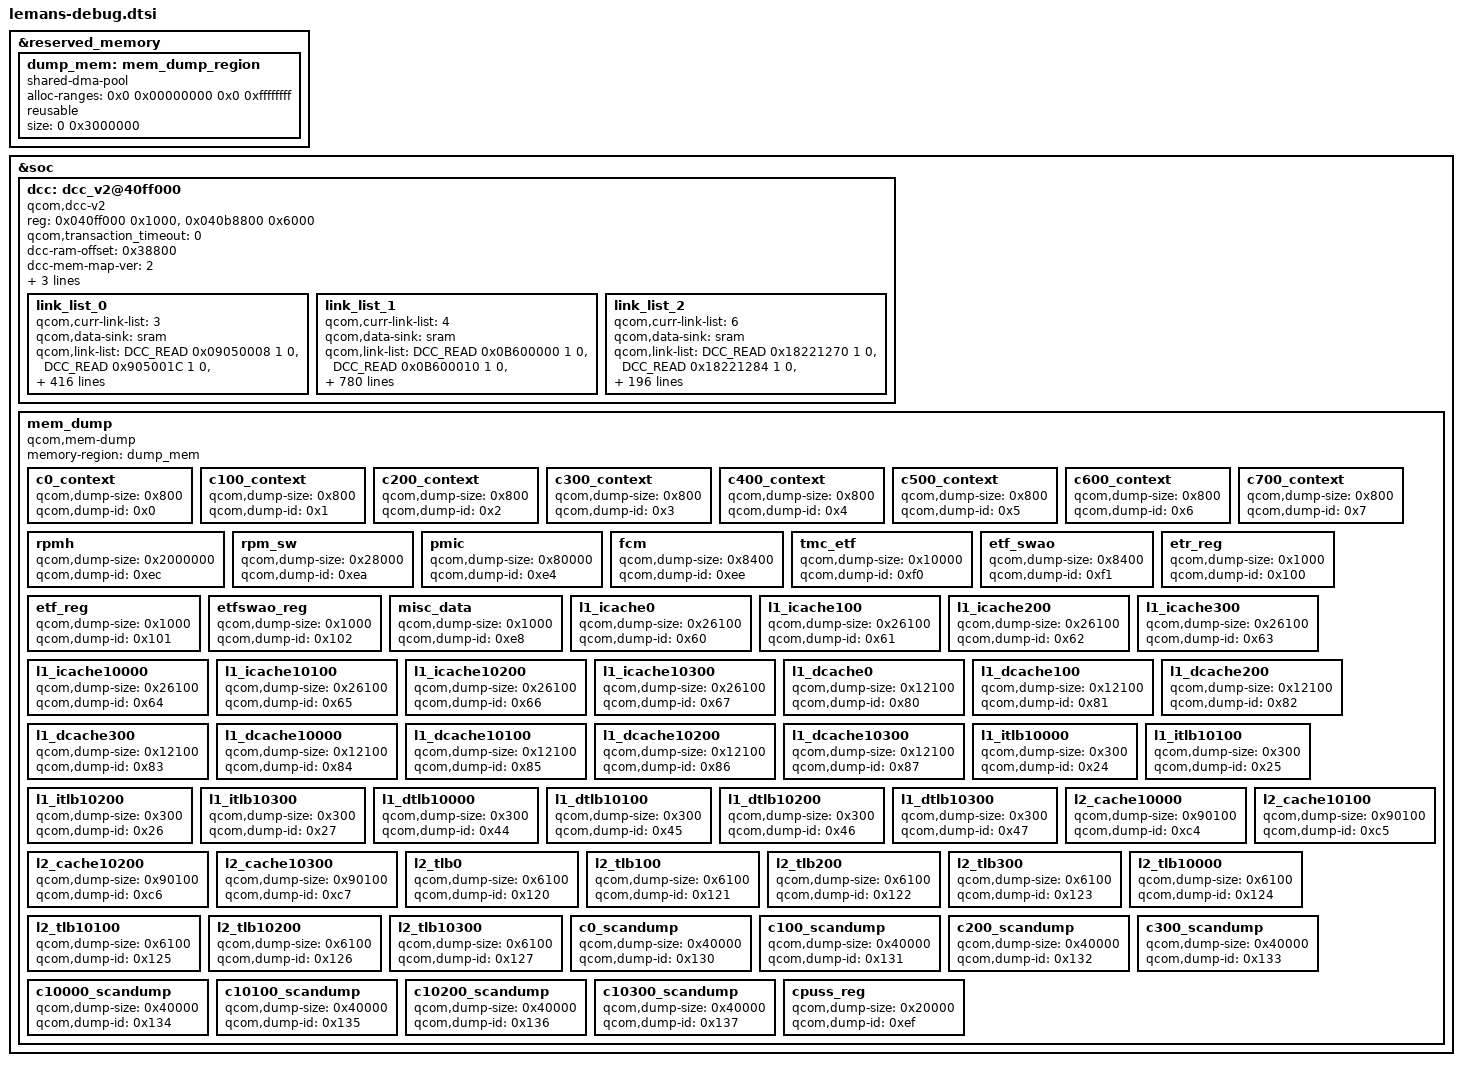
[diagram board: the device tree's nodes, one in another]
#include <dt-bindings/soc/qcom,dcc_v2.h>

&reserved_memory {
	#address-cells = <2>;
	#size-cells = <2>;
	ranges;

	dump_mem: mem_dump_region {
		compatible = "shared-dma-pool";
		alloc-ranges = <0x0 0x00000000 0x0 0xffffffff>;
		reusable;
		size = <0 0x3000000>;
	};
};

&soc {
	dcc: dcc_v2@40ff000 {
		compatible = "qcom,dcc-v2";
		reg = <0x040ff000 0x1000>,
			<0x040b8800 0x6000>;
		reg-names = "dcc-base", "dcc-ram-base";
		qcom,transaction_timeout = <0>;
		dcc-ram-offset = <0x38800>;
		dcc-mem-map-ver = <2>;
		per-ll-reg-cnt = <9>;
		ll-reg-offsets = <
			0x034 0x03C 0x040 0x044 0x04C 0x050 0x068 0x06C 0x038
			0x0B4 0x0BC 0x0C0 0x0C4 0x0CC 0x0D0 0x0E8 0x0EC 0x0B8
			0x134 0x13C 0x140 0x144 0x14C 0x150 0x168 0x16C 0x138
			0x1B4 0x1BC 0x1C0 0x1C4 0x1CC 0x1D0 0x1E8 0x1EC 0x1B8
			0x234 0x23C 0x240 0x244 0x24C 0x250 0x268 0x26C 0x238
			0x2B4 0x2BC 0x2C0 0x2C4 0x2CC 0x2D0 0x2E8 0x2EC 0x2B8
			0x334 0x33C 0x340 0x344 0x34C 0x350 0x368 0x36C 0x338
			0x3B4 0x3BC 0x3C0 0x3C4 0x3CC 0x3D0 0x3E8 0x3EC 0x3B8>;

		status = "okay";
		link_list_0 {
			qcom,curr-link-list = <3>;
			qcom,data-sink = "sram";
			qcom,link-list = <DCC_READ 0x09050008 1 0 >,
				<DCC_READ 0x905001C 1 0>,
				<DCC_READ 0x9050030 1 0>,
				<DCC_READ 0x9050050 1 0>,
				<DCC_READ 0x9050070 1 0>,
				<DCC_READ 0x9050948 1 0>,
				<DCC_READ 0x905104C 1 0>,
				<DCC_READ 0x09050078 1 0>,
				<DCC_READ 0x09050114 1 0>,
				<DCC_READ 0x90A0008 1 0>,
				<DCC_READ 0x90A000C 1 0>,
				<DCC_READ 0x90A0080 1 0>,
				<DCC_READ 0x90A1008 1 0>,
				<DCC_READ 0x90A100C 1 0>,
				<DCC_READ 0x90A1080 1 0>,
				<DCC_READ 0x90A80E4 1 0>,
				<DCC_READ 0x90A80E8 1 0>,
				<DCC_READ 0x90A816C 1 0>,
				<DCC_READ 0x90A8170 1 0>,
				<DCC_READ 0x90A80F8 1 0>,
				<DCC_READ 0x90A8180 1 0>,
				<DCC_READ 0x90A8184 1 0>,
				<DCC_READ 0x90A81A0 1 0>,
				<DCC_READ 0x90A81A4 1 0>,
				<DCC_READ 0x90A81C0 1 0>,
				<DCC_READ 0x90A81C4 1 0>,
				<DCC_READ 0x90A81E4 1 0>,
				<DCC_READ 0x90A81F4 1 0>,
				<DCC_READ 0x90A8204 1 0>,
				<DCC_READ 0x90A8218 1 0>,
				<DCC_READ 0x90A8228 1 0>,
				<DCC_READ 0x90A8264 1 0>,
				<DCC_READ 0x90A8268 1 0>,
				<DCC_READ 0x90A8270 1 0>,
				<DCC_READ 0x90A80FC 1 0>,
				<DCC_READ 0x90A8100 1 0>,
				<DCC_READ 0x90A8104 1 0>,
				<DCC_READ 0x90A8108 1 0>,
				<DCC_READ 0x90A8148 1 0>,
				<DCC_READ 0x90A814C 1 0>,
				<DCC_READ 0x90A8158 1 0>,
				<DCC_READ 0x90A815C 1 0>,
				<DCC_READ 0x90A8190 1 0>,
				<DCC_READ 0x90A8194 1 0>,
				<DCC_READ 0x90A81B0 1 0>,
				<DCC_READ 0x90A81B4 1 0>,
				<DCC_READ 0x90A81D0 1 0>,
				<DCC_READ 0x90A81D4 1 0>,
				<DCC_READ 0x90A84F4 1 0>,
				<DCC_READ 0x90A8138 1 0>,
				<DCC_READ 0x90A8150 1 0>,
				<DCC_READ 0x90A8160 1 0>,
				<DCC_READ 0x90A8198 1 0>,
				<DCC_READ 0x90A81B8 1 0>,
				<DCC_READ 0x90A81D8 1 0>,
				<DCC_READ 0x90A8280 1 0>,
				<DCC_READ 0x90A819C 1 0>,
				<DCC_READ 0x90A81BC 1 0>,
				<DCC_READ 0x90A81DC 1 0>,
				<DCC_READ 0x90A821C 1 0>,
				<DCC_READ 0x90A822C 1 0>,
				<DCC_READ 0x90A84F8 1 0>,
				<DCC_READ 0x90A9204 1 0>,
				<DCC_READ 0x90A880C 1 0>,
				<DCC_READ 0x90A8834 1 0>,
				<DCC_READ 0x90A8840 1 0>,
				<DCC_READ 0x90A8844 1 0>,
				<DCC_READ 0x90A8850 1 0>,
				<DCC_READ 0x90A8854 1 0>,
				<DCC_READ 0x90A8860 1 0>,
				<DCC_READ 0x90A8864 1 0>,
				<DCC_READ 0x90A8868 1 0>,
				<DCC_READ 0x90A8878 1 0>,
				<DCC_READ 0x90A9260 1 0>,
				<DCC_READ 0x90A8900 1 0>,
				<DCC_READ 0x90A9134 1 0>,
				<DCC_READ 0x90A9138 1 0>,
				<DCC_READ 0x90A8880 1 0>,
				<DCC_READ 0x90A8884 1 0>,
				<DCC_READ 0x90A8888 1 0>,
				<DCC_READ 0x90E0000 1 0>,
				<DCC_READ 0x90E0008 1 0>,
				<DCC_READ 0x90E0010 1 0>,
				<DCC_READ 0x90E0020 1 0>,
				<DCC_READ 0x90E0024 1 0>,
				<DCC_READ 0x90E0028 1 0>,
				<DCC_READ 0x90E002C 1 0>,
				<DCC_READ 0x90E0030 1 0>,
				<DCC_READ 0x90E0034 1 0>,
				<DCC_READ 0x90E0038 1 0>,
				<DCC_READ 0x90E003C 1 0>,
				<DCC_READ 0x90E0248 1 0>,
				<DCC_READ 0x90E3100 1 0>,
				<DCC_READ 0x90E4100 1 0>,
				<DCC_READ 0x90E4104 1 0>,
				<DCC_READ 0x90E4108 1 0>,
				<DCC_READ 0x90E410C 1 0>,
				<DCC_READ 0x90E4110 1 0>,
				<DCC_READ 0x90E4114 1 0>,
				<DCC_READ 0x90E4118 1 0>,
				<DCC_READ 0x90E5008 1 0>,
				<DCC_READ 0x90E5010 1 0>,
				<DCC_READ 0x90E5014 1 0>,
				<DCC_READ 0x90E5018 1 0>,
				<DCC_READ 0x9080024 1 0>,
				<DCC_READ 0x908002C 1 0>,
				<DCC_READ 0x9080034 1 0>,
				<DCC_READ 0x908003C 1 0>,
				<DCC_READ 0x9080044 1 0>,
				<DCC_READ 0x908004C 1 0>,
				<DCC_READ 0x9080054 1 0>,
				<DCC_READ 0x9080058 1 0>,
				<DCC_READ 0x908005C 1 0>,
				<DCC_READ 0x90800B8 1 0>,
				<DCC_READ 0x90800BC 1 0>,
				<DCC_READ 0x90800C8 1 0>,
				<DCC_READ 0x90800D4 1 0>,
				<DCC_READ 0x90800E0 1 0>,
				<DCC_READ 0x90800EC 1 0>,
				<DCC_READ 0x90800F8 1 0>,
				<DCC_READ 0x9080104 1 0>,
				<DCC_READ 0x9080108 1 0>,
				<DCC_READ 0x9080114 1 0>,
				<DCC_READ 0x9080144 1 0>,
				<DCC_READ 0x908014C 1 0>,
				<DCC_READ 0x9080168 1 0>,
				<DCC_READ 0x9080174 1 0>,
				<DCC_READ 0x90801AC 1 0>,
				<DCC_READ 0x90801B4 1 0>,
				<DCC_READ 0x90801BC 1 0>,
				<DCC_READ 0x90801C4 1 0>,
				<DCC_READ 0x90801CC 1 0>,
				<DCC_READ 0x90801D4 1 0>,
				<DCC_READ 0x90801DC 1 0>,
				<DCC_READ 0x90801E4 1 0>,
				<DCC_READ 0x90801EC 1 0>,
				<DCC_READ 0x90801F4 1 0>,
				<DCC_READ 0x90801F8 1 0>,
				<DCC_READ 0x90BA000 1 0>,
				<DCC_READ 0x90BA050 1 0>,
				<DCC_READ 0x090BA280 1 0>,
				<DCC_READ 0x090BA288 1 0>,
				<DCC_READ 0x9280610 1 0>,
				<DCC_READ 0x9280618 1 0>,
				<DCC_READ 0x928061C 1 0>,
				<DCC_READ 0x9280680 1 0>,
				<DCC_READ 0x9280684 1 0>,
				<DCC_READ 0x9280688 1 0>,
				<DCC_READ 0x928068C 1 0>,
				<DCC_READ 0x9380610 1 0>,
				<DCC_READ 0x9280614 1 0>,
				<DCC_READ 0x9380618 1 0>,
				<DCC_READ 0x938061C 1 0>,
				<DCC_READ 0x9380680 1 0>,
				<DCC_READ 0x9380684 1 0>,
				<DCC_READ 0x9380688 1 0>,
				<DCC_READ 0x938068C 1 0>,
				<DCC_READ 0x9480610 1 0>,
				<DCC_READ 0x9480614 1 0>,
				<DCC_READ 0x9480618 1 0>,
				<DCC_READ 0x948061C 1 0>,
				<DCC_READ 0x9480680 1 0>,
				<DCC_READ 0x9480684 1 0>,
				<DCC_READ 0x9480688 1 0>,
				<DCC_READ 0x948068C 1 0>,
				<DCC_READ 0x9580610 1 0>,
				<DCC_READ 0x9580614 1 0>,
				<DCC_READ 0x9580618 1 0>,
				<DCC_READ 0x958061C 1 0>,
				<DCC_READ 0x9580680 1 0>,
				<DCC_READ 0x9580684 1 0>,
				<DCC_READ 0x9580688 1 0>,
				<DCC_READ 0x958068C 1 0>,
				<DCC_READ 0x9680610 1 0>,
				<DCC_READ 0x9680614 1 0>,
				<DCC_READ 0x9680618 1 0>,
				<DCC_READ 0x968061C 1 0>,
				<DCC_READ 0x9680680 1 0>,
				<DCC_READ 0x9680684 1 0>,
				<DCC_READ 0x9680688 1 0>,
				<DCC_READ 0x968068C 1 0>,
				<DCC_READ 0x96B1300 4 0>,
				<DCC_READ 0x96B6138 3 0>,
				<DCC_READ 0x96B6D38 3 0>,
				<DCC_READ 0x96B7C04 3 0>,
				<DCC_READ 0x96B63D0 1 0>,
				<DCC_READ 0x96B63D8 1 0>,
				<DCC_READ 0x96B63E0 1 0>,
				<DCC_READ 0x96B6FD0 1 0>,
				<DCC_READ 0x96B6FD8 1 0>,
				<DCC_READ 0x96B6FE0 1 0>,
				<DCC_READ 0x96F1300 4 0>,
				<DCC_READ 0x96F6138 3 0>,
				<DCC_READ 0x96F6D38 3 0>,
				<DCC_READ 0x96F7C04 3 0>,
				<DCC_READ 0x96F63D0 1 0>,
				<DCC_READ 0x96F63D8 1 0>,
				<DCC_READ 0x96F63E0 1 0>,
				<DCC_READ 0x96F6FD0 1 0>,
				<DCC_READ 0x96F6FD8 1 0>,
				<DCC_READ 0x96F6FE0 1 0>,
				<DCC_READ 0x9731300 4 0>,
				<DCC_READ 0x9736138 3 0>,
				<DCC_READ 0x9736D38 3 0>,
				<DCC_READ 0x9737C04 3 0>,
				<DCC_READ 0x97363D0 1 0>,
				<DCC_READ 0x97363D8 1 0>,
				<DCC_READ 0x97363E0 1 0>,
				<DCC_READ 0x9736FD0 1 0>,
				<DCC_READ 0x9736FD8 1 0>,
				<DCC_READ 0x9736FE0 1 0>,
				<DCC_READ 0x9771300 4 0>,
				<DCC_READ 0x9776138 3 0>,
				<DCC_READ 0x9776D38 3 0>,
				<DCC_READ 0x9777C04 3 0>,
				<DCC_READ 0x97763D0 1 0>,
				<DCC_READ 0x97763D8 1 0>,
				<DCC_READ 0x97763E0 1 0>,
				<DCC_READ 0x9776FD0 1 0>,
				<DCC_READ 0x9776FD8 1 0>,
				<DCC_READ 0x9776FE0 1 0>,
				<DCC_READ 0x97B1300 4 0>,
				<DCC_READ 0x97B6138 3 0>,
				<DCC_READ 0x97B6D38 3 0>,
				<DCC_READ 0x97B7C04 3 0>,
				<DCC_READ 0x97B63D0 1 0>,
				<DCC_READ 0x97B63D8 1 0>,
				<DCC_READ 0x97B63E0 1 0>,
				<DCC_READ 0x97B6FD0 1 0>,
				<DCC_READ 0x97B6FD8 1 0>,
				<DCC_READ 0x97B6FE0 1 0>,
				<DCC_READ 0x97F1300 4 0>,
				<DCC_READ 0x97F6138 3 0>,
				<DCC_READ 0x97F6D38 3 0>,
				<DCC_READ 0x97F7C04 3 0>,
				<DCC_READ 0x97F63D0 1 0>,
				<DCC_READ 0x97F63D8 1 0>,
				<DCC_READ 0x97F63E0 1 0>,
				<DCC_READ 0x97F6FD0 1 0>,
				<DCC_READ 0x97F6FD8 1 0>,
				<DCC_READ 0x97F6FE0 1 0>,
				<DCC_READ 0x9831300 4 0>,
				<DCC_READ 0x9836138 3 0>,
				<DCC_READ 0x9836D38 3 0>,
				<DCC_READ 0x9837C04 3 0>,
				<DCC_READ 0x98363D0 1 0>,
				<DCC_READ 0x98363D8 1 0>,
				<DCC_READ 0x98363E0 1 0>,
				<DCC_READ 0x9836FD0 1 0>,
				<DCC_READ 0x9836FD8 1 0>,
				<DCC_READ 0x9836FE0 1 0>,
				<DCC_READ 0x9871300 4 0>,
				<DCC_READ 0x9876138 3 0>,
				<DCC_READ 0x9876D38 3 0>,
				<DCC_READ 0x9877C04 3 0>,
				<DCC_READ 0x98763D0 1 0>,
				<DCC_READ 0x98763D8 1 0>,
				<DCC_READ 0x98763E0 1 0>,
				<DCC_READ 0x9876FD0 1 0>,
				<DCC_READ 0x9876FD8 1 0>,
				<DCC_READ 0x9876FE0 1 0>,
				<DCC_READ 0x96B8D4C 1 0>,
				<DCC_READ 0x96B8D2C 1 0>,
				<DCC_READ 0x96B8D0C 1 0>,
				<DCC_READ 0x96F8D4C 1 0>,
				<DCC_READ 0x96F8D2C 1 0>,
				<DCC_READ 0x96F8D0C 1 0>,
				<DCC_READ 0x9738D4C 1 0>,
				<DCC_READ 0x9738D2C 1 0>,
				<DCC_READ 0x9738D0C 1 0>,
				<DCC_READ 0x9778D4C 1 0>,
				<DCC_READ 0x9778D2C 1 0>,
				<DCC_READ 0x9778D0C 1 0>,
				<DCC_READ 0x97B8D4C 1 0>,
				<DCC_READ 0x97B8D2C 1 0>,
				<DCC_READ 0x97B8D0C 1 0>,
				<DCC_READ 0x97F8D4C 1 0>,
				<DCC_READ 0x97F8D2C 1 0>,
				<DCC_READ 0x97F8D0C 1 0>,
				<DCC_READ 0x9838D4C 1 0>,
				<DCC_READ 0x9838D2C 1 0>,
				<DCC_READ 0x9838D0C 1 0>,
				<DCC_READ 0x9878D4C 1 0>,
				<DCC_READ 0x9878D2C 1 0>,
				<DCC_READ 0x9878D0C 1 0>,
				<DCC_READ 0x96B8D40 1 0>,
				<DCC_READ 0x96B8D50 1 0>,
				<DCC_READ 0x96B8D58 1 0>,
				<DCC_READ 0x96F8D40 1 0>,
				<DCC_READ 0x96F8D50 1 0>,
				<DCC_READ 0x96F8D58 1 0>,
				<DCC_READ 0x9738D40 1 0>,
				<DCC_READ 0x9738D50 1 0>,
				<DCC_READ 0x9738D58 1 0>,
				<DCC_READ 0x9778D40 1 0>,
				<DCC_READ 0x9778D50 1 0>,
				<DCC_READ 0x9778D58 1 0>,
				<DCC_READ 0x97B8D40 1 0>,
				<DCC_READ 0x97B8D50 1 0>,
				<DCC_READ 0x97B8D58 1 0>,
				<DCC_READ 0x97F8D40 1 0>,
				<DCC_READ 0x97F8D50 1 0>,
				<DCC_READ 0x97F8D58 1 0>,
				<DCC_READ 0x9838D40 1 0>,
				<DCC_READ 0x9838D50 1 0>,
				<DCC_READ 0x9838D58 1 0>,
				<DCC_READ 0x9878D40 1 0>,
				<DCC_READ 0x9878D50 1 0>,
				<DCC_READ 0x9878D58 1 0>,
				<DCC_READ 0x96B8D20 1 0>,
				<DCC_READ 0x96F8D20 1 0>,
				<DCC_READ 0x9738D20 1 0>,
				<DCC_READ 0x9778D20 1 0>,
				<DCC_READ 0x97B8D20 1 0>,
				<DCC_READ 0x97F8D20 1 0>,
				<DCC_READ 0x9838D20 1 0>,
				<DCC_READ 0x9878D20 1 0>,
				<DCC_READ 0x96B8904 1 0>,
				<DCC_READ 0x96B8308 2 0>,
				<DCC_READ 0x96B8108 1 0>,
				<DCC_READ 0x96B8508 1 0>,
				<DCC_READ 0x96F8904 1 0>,
				<DCC_READ 0x96F8308 2 0>,
				<DCC_READ 0x96F8108 1 0>,
				<DCC_READ 0x96F8508 1 0>,
				<DCC_READ 0x9738904 1 0>,
				<DCC_READ 0x9738308 2 0>,
				<DCC_READ 0x9738108 1 0>,
				<DCC_READ 0x9738508 1 0>,
				<DCC_READ 0x9778904 1 0>,
				<DCC_READ 0x9778308 2 0>,
				<DCC_READ 0x9778108 1 0>,
				<DCC_READ 0x9778508 1 0>,
				<DCC_READ 0x97B8904 1 0>,
				<DCC_READ 0x97B8308 2 0>,
				<DCC_READ 0x97B8108 1 0>,
				<DCC_READ 0x97B8508 1 0>,
				<DCC_READ 0x97F8904 1 0>,
				<DCC_READ 0x97F8308 2 0>,
				<DCC_READ 0x97F8108 1 0>,
				<DCC_READ 0x97F8508 1 0>,
				<DCC_READ 0x9838904 1 0>,
				<DCC_READ 0x9838308 2 0>,
				<DCC_READ 0x9838108 1 0>,
				<DCC_READ 0x9838508 1 0>,
				<DCC_READ 0x9878904 1 0>,
				<DCC_READ 0x9878308 2 0>,
				<DCC_READ 0x9878108 1 0>,
				<DCC_READ 0x9878508 1 0>,
				<DCC_WRITE 0x06E0A00C 0x00600007 1>,
				<DCC_WRITE 0x06E0A01C 0x00136800 1>,
				<DCC_READ 0x06E0A014 1 1>,
				<DCC_WRITE 0x06E0A01C 0x00136810 1>,
				<DCC_READ 0x06E0A014 1 1>,
				<DCC_WRITE 0x06E0A01C 0x00136820 1>,
				<DCC_READ 0x06E0A014 1 1>,
				<DCC_WRITE 0x06E0A01C 0x00136830 1>,
				<DCC_READ 0x06E0A014 1 1>,
				<DCC_WRITE 0x06E0A01C 0x00136840 1>,
				<DCC_READ 0x06E0A014 1 1>,
				<DCC_WRITE 0x06E0A01C 0x00136850 1>,
				<DCC_READ 0x06E0A014 1 1>,
				<DCC_WRITE 0x06E0A01C 0x00136860 1>,
				<DCC_READ 0x06E0A014 1 1>,
				<DCC_WRITE 0x06E0A01C 0x00136870 1>,
				<DCC_READ 0x06E0A014 1 1>,
				<DCC_WRITE 0x06E0A01C 0x0003e9a0 1>,
				<DCC_WRITE 0x06E0A01C 0x001368a0 1>,
				<DCC_READ 0x06E0A014 1 1>,
				<DCC_WRITE 0x06E0A01C 0x0003c0a0 1>,
				<DCC_WRITE 0x06E0A01C 0x001368a0 1>,
				<DCC_READ 0x06E0A014 1 1>,
				<DCC_WRITE 0x06E0A01C 0x0003d1a0 1>,
				<DCC_WRITE 0x06E0A01C 0x001368a0 1>,
				<DCC_READ 0x06E0A014 1 1>,
				<DCC_WRITE 0x06E0A01C 0x0003d2a0 1>,
				<DCC_WRITE 0x06E0A01C 0x001368a0 1>,
				<DCC_READ 0x06E0A014 1 1>,
				<DCC_WRITE 0x06E0A01C 0x0003d5a0 1>,
				<DCC_WRITE 0x06E0A01C 0x001368a0 1>,
				<DCC_READ 0x06E0A014 1 1>,
				<DCC_WRITE 0x06E0A01C 0x0003d6a0 1>,
				<DCC_WRITE 0x06E0A01C 0x001368a0 1>,
				<DCC_READ 0x06E0A014 1 1>,
				<DCC_WRITE 0x06E0A01C 0x0003e8a0 1>,
				<DCC_WRITE 0x06E0A01C 0x001368a0 1>,
				<DCC_READ 0x06E0A014 1 1>,
				<DCC_WRITE 0x06E0A01C 0x0003eea0 1>,
				<DCC_WRITE 0x06E0A01C 0x001368a0 1>,
				<DCC_READ 0x06E0A014 1 1>,
				<DCC_WRITE 0x06E0A01C 0x0003b1a0 1>,
				<DCC_WRITE 0x06E0A01C 0x001368a0 1>,
				<DCC_READ 0x06E0A014 1 1>,
				<DCC_WRITE 0x06E0A01C 0x0003b2a0 1>,
				<DCC_WRITE 0x06E0A01C 0x001368a0 1>,
				<DCC_READ 0x06E0A014 1 1>,
				<DCC_WRITE 0x06E0A01C 0x0003b5a0 1>,
				<DCC_WRITE 0x06E0A01C 0x001368a0 1>,
				<DCC_READ 0x06E0A014 1 1>,
				<DCC_WRITE 0x06E0A01C 0x0003b6a0 1>,
				<DCC_WRITE 0x06E0A01C 0x001368a0 1>,
				<DCC_READ 0x06E0A014 1 1>,
				<DCC_WRITE 0x06E0A01C 0x0003c2a0 1>,
				<DCC_WRITE 0x06E0A01C 0x001368a0 1>,
				<DCC_READ 0x06E0A014 1 1>,
				<DCC_WRITE 0x06E0A01C 0x0003c5a0 1>,
				<DCC_WRITE 0x06E0A01C 0x001368a0 1>,
				<DCC_READ 0x06E0A014 1 1>,
				<DCC_WRITE 0x06E0A01C 0x0003c6a0 1>,
				<DCC_WRITE 0x06E0A01C 0x001368a0 1>,
				<DCC_READ 0x06E0A014 1 1>,
				<DCC_WRITE 0x06E0A014 0x00020B38 1>,
				<DCC_WRITE 0x06E0A01C 0x000368B0 1>,
				<DCC_WRITE 0x06E0A01C 0x00000BA8 1>,
				<DCC_WRITE 0x06E0A01C 0x0013B6A0 1>,
				<DCC_WRITE 0x06E0A01C 0x00F1E000 1>,
				<DCC_WRITE 0x06E0A008 0x00000007 1>,
				<DCC_READ 0x09067E00 124 0>;
		};

		link_list_1 {
			qcom,curr-link-list = <4>;
			qcom,data-sink = "sram";
			qcom,link-list = <DCC_READ 0x0B600000 1 0>,
				<DCC_READ 0x0B600010 1 0>,
				<DCC_READ 0x0B600020 1 0>,
				<DCC_READ 0x0B600030 1 0>,
				<DCC_READ 0x0B600040 1 0>,
				<DCC_READ 0x0B600050 1 0>,
				<DCC_READ 0x0B600060 1 0>,
				<DCC_READ 0x0B600070 1 0>,
				<DCC_READ 0x0B600080 1 0>,
				<DCC_READ 0x0B600090 1 0>,
				<DCC_READ 0x0B6000A0 1 0>,
				<DCC_READ 0x0B6000B0 1 0>,
				<DCC_READ 0x0B6000C0 1 0>,
				<DCC_READ 0x0B6000D0 1 0>,
				<DCC_READ 0x0B610000 1 0>,
				<DCC_READ 0x0B610010 1 0>,
				<DCC_READ 0x0B610020 1 0>,
				<DCC_READ 0x0B610030 1 0>,
				<DCC_READ 0x0B610040 1 0>,
				<DCC_READ 0x0B610050 1 0>,
				<DCC_READ 0x0B610060 1 0>,
				<DCC_READ 0x0B610070 1 0>,
				<DCC_READ 0x0B610080 1 0>,
				<DCC_READ 0x0B610090 1 0>,
				<DCC_READ 0x0B6100A0 1 0>,
				<DCC_READ 0x0B6100B0 1 0>,
				<DCC_READ 0x0B6100C0 1 0>,
				<DCC_READ 0x0B6100D0 1 0>,
				<DCC_READ 0x0B620000 1 0>,
				<DCC_READ 0x0B620010 1 0>,
				<DCC_READ 0x0B620020 1 0>,
				<DCC_READ 0x0B620030 1 0>,
				<DCC_READ 0x0B620040 1 0>,
				<DCC_READ 0x0B620050 1 0>,
				<DCC_READ 0x0B620060 1 0>,
				<DCC_READ 0x0B620070 1 0>,
				<DCC_READ 0x0B620080 1 0>,
				<DCC_READ 0x0B620090 1 0>,
				<DCC_READ 0x0B6200A0 1 0>,
				<DCC_READ 0x0B6200B0 1 0>,
				<DCC_READ 0x0B6200C0 1 0>,
				<DCC_READ 0x0B6200D0 1 0>,
				<DCC_READ 0x0B630000 1 0>,
				<DCC_READ 0x0B630010 1 0>,
				<DCC_READ 0x0B630020 1 0>,
				<DCC_READ 0x0B630030 1 0>,
				<DCC_READ 0x0B630040 1 0>,
				<DCC_READ 0x0B630050 1 0>,
				<DCC_READ 0x0B630060 1 0>,
				<DCC_READ 0x0B630070 1 0>,
				<DCC_READ 0x0B630080 1 0>,
				<DCC_READ 0x0B630090 1 0>,
				<DCC_READ 0x0B6300A0 1 0>,
				<DCC_READ 0x0B6300B0 1 0>,
				<DCC_READ 0x0B6300C0 1 0>,
				<DCC_READ 0x0B6300D0 1 0>,
				<DCC_READ 0x0B640000 1 0>,
				<DCC_READ 0x0B640010 1 0>,
				<DCC_READ 0x0B640020 1 0>,
				<DCC_READ 0x0B640030 1 0>,
				<DCC_READ 0x0B640040 1 0>,
				<DCC_READ 0x0B640050 1 0>,
				<DCC_READ 0x0B640060 1 0>,
				<DCC_READ 0x0B640070 1 0>,
				<DCC_READ 0x0B640080 1 0>,
				<DCC_READ 0x0B640090 1 0>,
				<DCC_READ 0x0B6400A0 1 0>,
				<DCC_READ 0x0B6400B0 1 0>,
				<DCC_READ 0x0B6400C0 1 0>,
				<DCC_READ 0x0B6400D0 1 0>,
				<DCC_READ 0x0B650000 1 0>,
				<DCC_READ 0x0B650010 1 0>,
				<DCC_READ 0x0B650020 1 0>,
				<DCC_READ 0x0B650030 1 0>,
				<DCC_READ 0x0B650040 1 0>,
				<DCC_READ 0x0B650050 1 0>,
				<DCC_READ 0x0B650060 1 0>,
				<DCC_READ 0x0B650070 1 0>,
				<DCC_READ 0x0B650080 1 0>,
				<DCC_READ 0x0B650090 1 0>,
				<DCC_READ 0x0B6500A0 1 0>,
				<DCC_READ 0x0B6500B0 1 0>,
				<DCC_READ 0x0B6500C0 1 0>,
				<DCC_READ 0x0B6500D0 1 0>,
				<DCC_READ 0x0B660000 1 0>,
				<DCC_READ 0x0B660010 1 0>,
				<DCC_READ 0x0B660020 1 0>,
				<DCC_READ 0x0B660030 1 0>,
				<DCC_READ 0x0B660040 1 0>,
				<DCC_READ 0x0B660050 1 0>,
				<DCC_READ 0x0B660060 1 0>,
				<DCC_READ 0x0B660070 1 0>,
				<DCC_READ 0x0B660080 1 0>,
				<DCC_READ 0x0B660090 1 0>,
				<DCC_READ 0x0B6600A0 1 0>,
				<DCC_READ 0x0B6600B0 1 0>,
				<DCC_READ 0x0B6600C0 1 0>,
				<DCC_READ 0x0B6600D0 1 0>,
				<DCC_READ 0x0B670000 1 0>,
				<DCC_READ 0x0B670010 1 0>,
				<DCC_READ 0x0B670020 1 0>,
				<DCC_READ 0x0B670030 1 0>,
				<DCC_READ 0x0B670040 1 0>,
				<DCC_READ 0x0B670050 1 0>,
				<DCC_READ 0x0B670060 1 0>,
				<DCC_READ 0x0B670070 1 0>,
				<DCC_READ 0x0B670080 1 0>,
				<DCC_READ 0x0B670090 1 0>,
				<DCC_READ 0x0B6700A0 1 0>,
				<DCC_READ 0x0B6700B0 1 0>,
				<DCC_READ 0x0B6700C0 1 0>,
				<DCC_READ 0x0B6700D0 1 0>,
				<DCC_READ 0x0B680000 1 0>,
				<DCC_READ 0x0B680010 1 0>,
				<DCC_READ 0x0B680020 1 0>,
				<DCC_READ 0x0B680030 1 0>,
				<DCC_READ 0x0B680040 1 0>,
				<DCC_READ 0x0B680050 1 0>,
				<DCC_READ 0x0B680060 1 0>,
				<DCC_READ 0x0B680070 1 0>,
				<DCC_READ 0x0B680080 1 0>,
				<DCC_READ 0x0B680090 1 0>,
				<DCC_READ 0x0B6800A0 1 0>,
				<DCC_READ 0x0B6800B0 1 0>,
				<DCC_READ 0x0B6800C0 1 0>,
				<DCC_READ 0x0B6800D0 1 0>,
				<DCC_READ 0x0B690000 1 0>,
				<DCC_READ 0x0B690010 1 0>,
				<DCC_READ 0x0B690020 1 0>,
				<DCC_READ 0x0B690030 1 0>,
				<DCC_READ 0x0B690040 1 0>,
				<DCC_READ 0x0B690050 1 0>,
				<DCC_READ 0x0B690060 1 0>,
				<DCC_READ 0x0B690070 1 0>,
				<DCC_READ 0x0B690080 1 0>,
				<DCC_READ 0x0B690090 1 0>,
				<DCC_READ 0x0B6900A0 1 0>,
				<DCC_READ 0x0B6900B0 1 0>,
				<DCC_READ 0x0B6900C0 1 0>,
				<DCC_READ 0x0B6900D0 1 0>,
				<DCC_READ 0x0B6A0000 1 0>,
				<DCC_READ 0x0B6A0010 1 0>,
				<DCC_READ 0x0B6A0020 1 0>,
				<DCC_READ 0x0B6A0030 1 0>,
				<DCC_READ 0x0B6A0040 1 0>,
				<DCC_READ 0x0B6A0050 1 0>,
				<DCC_READ 0x0B6A0060 1 0>,
				<DCC_READ 0x0B6A0070 1 0>,
				<DCC_READ 0x0B6A0080 1 0>,
				<DCC_READ 0x0B6A0090 1 0>,
				<DCC_READ 0x0B6A00A0 1 0>,
				<DCC_READ 0x0B6A00B0 1 0>,
				<DCC_READ 0x0B6A00C0 1 0>,
				<DCC_READ 0x0B6A00D0 1 0>,
				<DCC_READ 0x0B6B0000 1 0>,
				<DCC_READ 0x0B6B0010 1 0>,
				<DCC_READ 0x0B6B0020 1 0>,
				<DCC_READ 0x0B6B0030 1 0>,
				<DCC_READ 0x0B6B0040 1 0>,
				<DCC_READ 0x0B6B0050 1 0>,
				<DCC_READ 0x0B6B0060 1 0>,
				<DCC_READ 0x0B6B0070 1 0>,
				<DCC_READ 0x0B6B0080 1 0>,
				<DCC_READ 0x0B6B0090 1 0>,
				<DCC_READ 0x0B6B00A0 1 0>,
				<DCC_READ 0x0B6B00B0 1 0>,
				<DCC_READ 0x0B6B00C0 1 0>,
				<DCC_READ 0x0B6B00D0 1 0>,
				<DCC_READ 0x0B6C0000 1 0>,
				<DCC_READ 0x0B6C0010 1 0>,
				<DCC_READ 0x0B6C0020 1 0>,
				<DCC_READ 0x0B6C0030 1 0>,
				<DCC_READ 0x0B6C0040 1 0>,
				<DCC_READ 0x0B6C0050 1 0>,
				<DCC_READ 0x0B6C0060 1 0>,
				<DCC_READ 0x0B6C0070 1 0>,
				<DCC_READ 0x0B6C0080 1 0>,
				<DCC_READ 0x0B6C0090 1 0>,
				<DCC_READ 0x0B6C00A0 1 0>,
				<DCC_READ 0x0B6C00B0 1 0>,
				<DCC_READ 0x0B6C00C0 1 0>,
				<DCC_READ 0x0B6C00D0 1 0>,
				<DCC_READ 0x0B6D0000 1 0>,
				<DCC_READ 0x0B6D0010 1 0>,
				<DCC_READ 0x0B6D0020 1 0>,
				<DCC_READ 0x0B6D0030 1 0>,
				<DCC_READ 0x0B6D0040 1 0>,
				<DCC_READ 0x0B6D0050 1 0>,
				<DCC_READ 0x0B6D0060 1 0>,
				<DCC_READ 0x0B6D0070 1 0>,
				<DCC_READ 0x0B6D0080 1 0>,
				<DCC_READ 0x0B6D0090 1 0>,
				<DCC_READ 0x0B6D00A0 1 0>,
				<DCC_READ 0x0B6D00B0 1 0>,
				<DCC_READ 0x0B6D00C0 1 0>,
				<DCC_READ 0x0B6D00D0 1 0>,
				<DCC_READ 0x0B6E0000 1 0>,
				<DCC_READ 0x0B6E0010 1 0>,
				<DCC_READ 0x0B6E0020 1 0>,
				<DCC_READ 0x0B6E0030 1 0>,
				<DCC_READ 0x0B6E0040 1 0>,
				<DCC_READ 0x0B6E0050 1 0>,
				<DCC_READ 0x0B6E0060 1 0>,
				<DCC_READ 0x0B6E0070 1 0>,
				<DCC_READ 0x0B6E0080 1 0>,
				<DCC_READ 0x0B6E0090 1 0>,
				<DCC_READ 0x0B6E00A0 1 0>,
				<DCC_READ 0x0B6E00B0 1 0>,
				<DCC_READ 0x0B6E00C0 1 0>,
				<DCC_READ 0x0B6E00D0 1 0>,
				<DCC_READ 0x0B6F0000 1 0>,
				<DCC_READ 0x0B6F0010 1 0>,
				<DCC_READ 0x0B6F0020 1 0>,
				<DCC_READ 0x0B6F0030 1 0>,
				<DCC_READ 0x0B6F0040 1 0>,
				<DCC_READ 0x0B6F0050 1 0>,
				<DCC_READ 0x0B6F0060 1 0>,
				<DCC_READ 0x0B6F0070 1 0>,
				<DCC_READ 0x0B6F0080 1 0>,
				<DCC_READ 0x0B6F0090 1 0>,
				<DCC_READ 0x0B6F00A0 1 0>,
				<DCC_READ 0x0B6F00B0 1 0>,
				<DCC_READ 0x0B6F00C0 1 0>,
				<DCC_READ 0x0B6F00D0 1 0>,
				<DCC_READ 0x0B700000 1 0>,
				<DCC_READ 0x0B700010 1 0>,
				<DCC_READ 0x0B700020 1 0>,
				<DCC_READ 0x0B700030 1 0>,
				<DCC_READ 0x0B700040 1 0>,
				<DCC_READ 0x0B700050 1 0>,
				<DCC_READ 0x0B700060 1 0>,
				<DCC_READ 0x0B700070 1 0>,
				<DCC_READ 0x0B700080 1 0>,
				<DCC_READ 0x0B700090 1 0>,
				<DCC_READ 0x0B7000A0 1 0>,
				<DCC_READ 0x0B7000B0 1 0>,
				<DCC_READ 0x0B7000C0 1 0>,
				<DCC_READ 0x0B7000D0 1 0>,
				<DCC_READ 0x0B710000 1 0>,
				<DCC_READ 0x0B710010 1 0>,
				<DCC_READ 0x0B710020 1 0>,
				<DCC_READ 0x0B710030 1 0>,
				<DCC_READ 0x0B710040 1 0>,
				<DCC_READ 0x0B710050 1 0>,
				<DCC_READ 0x0B710060 1 0>,
				<DCC_READ 0x0B710070 1 0>,
				<DCC_READ 0x0B710080 1 0>,
				<DCC_READ 0x0B710090 1 0>,
				<DCC_READ 0x0B7100A0 1 0>,
				<DCC_READ 0x0B7100B0 1 0>,
				<DCC_READ 0x0B7100C0 1 0>,
				<DCC_READ 0x0B7100D0 1 0>,
				<DCC_READ 0x0B720000 1 0>,
				<DCC_READ 0x0B720010 1 0>,
				<DCC_READ 0x0B720020 1 0>,
				<DCC_READ 0x0B720030 1 0>,
				<DCC_READ 0x0B720040 1 0>,
				<DCC_READ 0x0B720050 1 0>,
				<DCC_READ 0x0B720060 1 0>,
				<DCC_READ 0x0B720070 1 0>,
				<DCC_READ 0x0B720080 1 0>,
				<DCC_READ 0x0B720090 1 0>,
				<DCC_READ 0x0B7200A0 1 0>,
				<DCC_READ 0x0B7200B0 1 0>,
				<DCC_READ 0x0B7200C0 1 0>,
				<DCC_READ 0x0B7200D0 1 0>,
				<DCC_READ 0x0B730000 1 0>,
				<DCC_READ 0x0B730010 1 0>,
				<DCC_READ 0x0B730020 1 0>,
				<DCC_READ 0x0B730030 1 0>,
				<DCC_READ 0x0B730040 1 0>,
				<DCC_READ 0x0B730050 1 0>,
				<DCC_READ 0x0B730060 1 0>,
				<DCC_READ 0x0B730070 1 0>,
				<DCC_READ 0x0B730080 1 0>,
				<DCC_READ 0x0B730090 1 0>,
				<DCC_READ 0x0B7300A0 1 0>,
				<DCC_READ 0x0B7300B0 1 0>,
				<DCC_READ 0x0B7300C0 1 0>,
				<DCC_READ 0x0B7300D0 1 0>,
				<DCC_READ 0x0B7D0000 1 0>,
				<DCC_READ 0x0B7D0010 1 0>,
				<DCC_READ 0x0B7D0020 1 0>,
				<DCC_READ 0x0B7D0030 1 0>,
				<DCC_READ 0x0B7D0040 1 0>,
				<DCC_READ 0x0B7D0050 1 0>,
				<DCC_READ 0x0B7D0060 1 0>,
				<DCC_READ 0x0B7D0070 1 0>,
				<DCC_READ 0x0B7D0080 1 0>,
				<DCC_READ 0x0B7D0090 1 0>,
				<DCC_READ 0x0B7D00A0 1 0>,
				<DCC_READ 0x0B7D00B0 1 0>,
				<DCC_READ 0x0B7D00C0 1 0>,
				<DCC_READ 0x0B7D00D0 1 0>,
				<DCC_READ 0x0B7D1000 1 0>,
				<DCC_READ 0x0B7D1010 1 0>,
				<DCC_READ 0x0B7D1020 1 0>,
				<DCC_READ 0x0B7D1030 1 0>,
				<DCC_READ 0x0B7D1040 1 0>,
				<DCC_READ 0x0B7D1050 1 0>,
				<DCC_READ 0x0B7D1060 1 0>,
				<DCC_READ 0x0B7D1070 1 0>,
				<DCC_READ 0x0B7D1080 1 0>,
				<DCC_READ 0x0B7D1090 1 0>,
				<DCC_READ 0x0B7D10A0 1 0>,
				<DCC_READ 0x0B7D10B0 1 0>,
				<DCC_READ 0x0B7D10C0 1 0>,
				<DCC_READ 0x0B7D10D0 1 0>,
				<DCC_READ 0x0B7D2000 1 0>,
				<DCC_READ 0x0B7D2010 1 0>,
				<DCC_READ 0x0B7D2020 1 0>,
				<DCC_READ 0x0B7D2030 1 0>,
				<DCC_READ 0x0B7D2040 1 0>,
				<DCC_READ 0x0B7D2050 1 0>,
				<DCC_READ 0x0B7D2060 1 0>,
				<DCC_READ 0x0B7D2070 1 0>,
				<DCC_READ 0x0B7D2080 1 0>,
				<DCC_READ 0x0B7D2090 1 0>,
				<DCC_READ 0x0B7D20A0 1 0>,
				<DCC_READ 0x0B7D20B0 1 0>,
				<DCC_READ 0x0B7D20C0 1 0>,
				<DCC_READ 0x0B7D20D0 1 0>,
				<DCC_READ 0x0B7D3000 1 0>,
				<DCC_READ 0x0B7D3010 1 0>,
				<DCC_READ 0x0B7D3020 1 0>,
				<DCC_READ 0x0B7D3030 1 0>,
				<DCC_READ 0x0B7D3040 1 0>,
				<DCC_READ 0x0B7D3050 1 0>,
				<DCC_READ 0x0B7D3060 1 0>,
				<DCC_READ 0x0B7D3070 1 0>,
				<DCC_READ 0x0B7D3080 1 0>,
				<DCC_READ 0x0B7D3090 1 0>,
				<DCC_READ 0x0B7D30A0 1 0>,
				<DCC_READ 0x0B7D30B0 1 0>,
				<DCC_READ 0x0B7D30C0 1 0>,
				<DCC_READ 0x0B7D30D0 1 0>,
				<DCC_READ 0x0B7D4000 1 0>,
				<DCC_READ 0x0B7D4010 1 0>,
				<DCC_READ 0x0B7D4020 1 0>,
				<DCC_READ 0x0B7D4030 1 0>,
				<DCC_READ 0x0B7D4040 1 0>,
				<DCC_READ 0x0B7D4050 1 0>,
				<DCC_READ 0x0B7D4060 1 0>,
				<DCC_READ 0x0B7D4070 1 0>,
				<DCC_READ 0x0B7D4080 1 0>,
				<DCC_READ 0x0B7D4090 1 0>,
				<DCC_READ 0x0B7D40A0 1 0>,
				<DCC_READ 0x0B7D40B0 1 0>,
				<DCC_READ 0x0B7D40C0 1 0>,
				<DCC_READ 0x0B7D40D0 1 0>,
				<DCC_READ 0x0B7D5000 1 0>,
				<DCC_READ 0x0B7D5010 1 0>,
				<DCC_READ 0x0B7D5020 1 0>,
				<DCC_READ 0x0B7D5030 1 0>,
				<DCC_READ 0x0B7D5040 1 0>,
				<DCC_READ 0x0B7D5050 1 0>,
				<DCC_READ 0x0B7D5060 1 0>,
				<DCC_READ 0x0B7D5070 1 0>,
				<DCC_READ 0x0B7D5080 1 0>,
				<DCC_READ 0x0B7D5090 1 0>,
				<DCC_READ 0x0B7D50A0 1 0>,
				<DCC_READ 0x0B7D50B0 1 0>,
				<DCC_READ 0x0B7D50C0 1 0>,
				<DCC_READ 0x0B7D50D0 1 0>,
				<DCC_READ 0x0B7D6000 1 0>,
				<DCC_READ 0x0B7D6010 1 0>,
				<DCC_READ 0x0B7D6020 1 0>,
				<DCC_READ 0x0B7D6030 1 0>,
				<DCC_READ 0x0B7D6040 1 0>,
				<DCC_READ 0x0B7D6050 1 0>,
				<DCC_READ 0x0B7D6060 1 0>,
				<DCC_READ 0x0B7D6070 1 0>,
				<DCC_READ 0x0B7D6080 1 0>,
				<DCC_READ 0x0B7D6090 1 0>,
				<DCC_READ 0x0B7D60A0 1 0>,
				<DCC_READ 0x0B7D60B0 1 0>,
				<DCC_READ 0x0B7D60C0 1 0>,
				<DCC_READ 0x0B7D60D0 1 0>,
				<DCC_READ 0x0B7D7000 1 0>,
				<DCC_READ 0x0B7D7010 1 0>,
				<DCC_READ 0x0B7D7020 1 0>,
				<DCC_READ 0x0B7D7030 1 0>,
				<DCC_READ 0x0B7D7040 1 0>,
				<DCC_READ 0x0B7D7050 1 0>,
				<DCC_READ 0x0B7D7060 1 0>,
				<DCC_READ 0x0B7D7070 1 0>,
				<DCC_READ 0x0B7D7080 1 0>,
				<DCC_READ 0x0B7D7090 1 0>,
				<DCC_READ 0x0B7D70A0 1 0>,
				<DCC_READ 0x0B7D70B0 1 0>,
				<DCC_READ 0x0B7D70C0 1 0>,
				<DCC_READ 0x0B7D70D0 1 0>,
				<DCC_READ 0x0B7D8000 1 0>,
				<DCC_READ 0x0B7D8010 1 0>,
				<DCC_READ 0x0B7D8020 1 0>,
				<DCC_READ 0x0B7D8030 1 0>,
				<DCC_READ 0x0B7D8040 1 0>,
				<DCC_READ 0x0B7D8050 1 0>,
				<DCC_READ 0x0B7D8060 1 0>,
				<DCC_READ 0x0B7D8070 1 0>,
				<DCC_READ 0x0B7D8080 1 0>,
				<DCC_READ 0x0B7D8090 1 0>,
				<DCC_READ 0x0B7D80A0 1 0>,
				<DCC_READ 0x0B7D80B0 1 0>,
				<DCC_READ 0x0B7D80C0 1 0>,
				<DCC_READ 0x0B7D80D0 1 0>,
				<DCC_READ 0x0B7D9000 1 0>,
				<DCC_READ 0x0B7D9010 1 0>,
				<DCC_READ 0x0B7D9020 1 0>,
				<DCC_READ 0x0B7D9030 1 0>,
				<DCC_READ 0x0B7D9040 1 0>,
				<DCC_READ 0x0B7D9050 1 0>,
				<DCC_READ 0x0B7D9060 1 0>,
				<DCC_READ 0x0B7D9070 1 0>,
				<DCC_READ 0x0B7D9080 1 0>,
				<DCC_READ 0x0B7D9090 1 0>,
				<DCC_READ 0x0B7D90A0 1 0>,
				<DCC_READ 0x0B7D90B0 1 0>,
				<DCC_READ 0x0B7D90C0 1 0>,
				<DCC_READ 0x0B7D90D0 1 0>,
				<DCC_READ 0x0B7DA000 1 0>,
				<DCC_READ 0x0B7DA010 1 0>,
				<DCC_READ 0x0B7DA020 1 0>,
				<DCC_READ 0x0B7DA030 1 0>,
				<DCC_READ 0x0B7DA040 1 0>,
				<DCC_READ 0x0B7DA050 1 0>,
				<DCC_READ 0x0B7DA060 1 0>,
				<DCC_READ 0x0B7DA070 1 0>,
				<DCC_READ 0x0B7DA080 1 0>,
				<DCC_READ 0x0B7DA090 1 0>,
				<DCC_READ 0x0B7DA0A0 1 0>,
				<DCC_READ 0x0B7DA0B0 1 0>,
				<DCC_READ 0x0B7DA0C0 1 0>,
				<DCC_READ 0x0B7DA0D0 1 0>,
				<DCC_READ 0x0B7DB000 1 0>,
				<DCC_READ 0x0B7DB010 1 0>,
				<DCC_READ 0x0B7DB020 1 0>,
				<DCC_READ 0x0B7DB030 1 0>,
				<DCC_READ 0x0B7DB040 1 0>,
				<DCC_READ 0x0B7DB050 1 0>,
				<DCC_READ 0x0B7DB060 1 0>,
				<DCC_READ 0x0B7DB070 1 0>,
				<DCC_READ 0x0B7DB080 1 0>,
				<DCC_READ 0x0B7DB090 1 0>,
				<DCC_READ 0x0B7DB0A0 1 0>,
				<DCC_READ 0x0B7DB0B0 1 0>,
				<DCC_READ 0x0B7DB0C0 1 0>,
				<DCC_READ 0x0B7DB0D0 1 0>,
				<DCC_READ 0x0B7DC000 1 0>,
				<DCC_READ 0x0B7DC010 1 0>,
				<DCC_READ 0x0B7DC020 1 0>,
				<DCC_READ 0x0B7DC030 1 0>,
				<DCC_READ 0x0B7DC040 1 0>,
				<DCC_READ 0x0B7DC050 1 0>,
				<DCC_READ 0x0B7DC060 1 0>,
				<DCC_READ 0x0B7DC070 1 0>,
				<DCC_READ 0x0B7DC080 1 0>,
				<DCC_READ 0x0B7DC090 1 0>,
				<DCC_READ 0x0B7DC0A0 1 0>,
				<DCC_READ 0x0B7DC0B0 1 0>,
				<DCC_READ 0x0B7DC0C0 1 0>,
				<DCC_READ 0x0B7DC0D0 1 0>,
				<DCC_READ 0x0B7DD000 1 0>,
				<DCC_READ 0x0B7DD010 1 0>,
				<DCC_READ 0x0B7DD020 1 0>,
				<DCC_READ 0x0B7DD030 1 0>,
				<DCC_READ 0x0B7DD040 1 0>,
				<DCC_READ 0x0B7DD050 1 0>,
				<DCC_READ 0x0B7DD060 1 0>,
				<DCC_READ 0x0B7DD070 1 0>,
				<DCC_READ 0x0B7DD080 1 0>,
				<DCC_READ 0x0B7DD090 1 0>,
				<DCC_READ 0x0B7DD0A0 1 0>,
				<DCC_READ 0x0B7DD0B0 1 0>,
				<DCC_READ 0x0B7DD0C0 1 0>,
				<DCC_READ 0x0B7DD0D0 1 0>,
				<DCC_READ 0x0B7DE000 1 0>,
				<DCC_READ 0x0B7DE010 1 0>,
				<DCC_READ 0x0B7DE020 1 0>,
				<DCC_READ 0x0B7DE030 1 0>,
				<DCC_READ 0x0B7DE040 1 0>,
				<DCC_READ 0x0B7DE050 1 0>,
				<DCC_READ 0x0B7DE060 1 0>,
				<DCC_READ 0x0B7DE070 1 0>,
				<DCC_READ 0x0B7DE080 1 0>,
				<DCC_READ 0x0B7DE090 1 0>,
				<DCC_READ 0x0B7DE0A0 1 0>,
				<DCC_READ 0x0B7DE0B0 1 0>,
				<DCC_READ 0x0B7DE0C0 1 0>,
				<DCC_READ 0x0B7DE0D0 1 0>,
				<DCC_READ 0x0B7DF000 1 0>,
				<DCC_READ 0x0B7DF010 1 0>,
				<DCC_READ 0x0B7DF020 1 0>,
				<DCC_READ 0x0B7DF030 1 0>,
				<DCC_READ 0x0B7DF040 1 0>,
				<DCC_READ 0x0B7DF050 1 0>,
				<DCC_READ 0x0B7DF060 1 0>,
				<DCC_READ 0x0B7DF070 1 0>,
				<DCC_READ 0x0B7DF080 1 0>,
				<DCC_READ 0x0B7DF090 1 0>,
				<DCC_READ 0x0B7DF0A0 1 0>,
				<DCC_READ 0x0B7DF0B0 1 0>,
				<DCC_READ 0x0B7DF0C0 1 0>,
				<DCC_READ 0x0B7DF0D0 1 0>,
				<DCC_READ 0x0B7F0000 14 0>,
				<DCC_READ 0x0B7F00C0 14 0>,
				<DCC_READ 0x0B7F4500 1 0>,
				<DCC_READ 0x0B7F4540 1 0>,
				<DCC_READ 0x0B7F4580 1 0>,
				<DCC_READ 0x0B7F45C0 1 0>,
				<DCC_READ 0x0B7F4600 1 0>,
				<DCC_READ 0x0B7F4640 1 0>,
				<DCC_READ 0x0B7F4680 1 0>,
				<DCC_READ 0x0B7F46C0 1 0>,
				<DCC_READ 0x0B7F4700 1 0>,
				<DCC_READ 0x0B7F4740 1 0>,
				<DCC_READ 0x0B7F4780 1 0>,
				<DCC_READ 0x0B7F47C0 1 0>,
				<DCC_READ 0x0B7F4800 1 0>,
				<DCC_READ 0x0B7F4840 1 0>,
				<DCC_READ 0x0BDE093C 1 0>,
				<DCC_READ 0x0BA00000 2 0>,
				<DCC_READ 0x0BA0000C 1 0>,
				<DCC_READ 0x0BA00010 4 0>,
				<DCC_READ 0x0BA00024 8 0>,
				<DCC_READ 0x0BA00050 13 0>,
				<DCC_READ 0x0BA00088 5 0>,
				<DCC_READ 0x0BA000A0 4 0>,
				<DCC_READ 0x0BA000B4 11 0>,
				<DCC_READ 0x0BA000E4 3 0>,
				<DCC_READ 0x0BA000F4 3 0>,
				<DCC_READ 0x0BA20000 56 0>,
				<DCC_READ 0x0BA200E4 3 0>,
				<DCC_READ 0x0BA200F4 3 0>,
				<DCC_READ 0x0BA40000 3 0>,
				<DCC_READ 0x0BA40010 6 0>,
				<DCC_READ 0x0BA40030 5 0>,
				<DCC_READ 0x0BA4004C 1 0>,
				<DCC_READ 0x0BA40058 9 0>,
				<DCC_READ 0x0BA40088 8 0>,
				<DCC_READ 0x0BA400B4 11 0>,
				<DCC_READ 0x0BA400E4 3 0>,
				<DCC_READ 0x0BA400F4 3 0>,
				<DCC_READ 0x0BA50000 3 0>,
				<DCC_READ 0x0BA50010 2 0>,
				<DCC_READ 0x0BA50024 1 0>,
				<DCC_READ 0x0BA50030 2 0>,
				<DCC_READ 0x0BA50040 4 0>,
				<DCC_READ 0x0BA50058 4 0>,
				<DCC_READ 0x0BA50070 3 0>,
				<DCC_READ 0x0BA50088 3 0>,
				<DCC_READ 0x0BA500A0 2 0>,
				<DCC_READ 0x0BA500B4 19 0>,
				<DCC_READ 0x0BA60000 3 0>,
				<DCC_READ 0x0BA60010 2 0>,
				<DCC_READ 0x0BA60024 1 0>,
				<DCC_READ 0x0BA60030 2 0>,
				<DCC_READ 0x0BA60040 1 0>,
				<DCC_READ 0x0BA6004C 1 0>,
				<DCC_READ 0x0BA60058 4 0>,
				<DCC_READ 0x0BA60070 3 0>,
				<DCC_READ 0x0BA600A0 2 0>,
				<DCC_READ 0x0BA600B4 11 0>,
				<DCC_READ 0x0BA600E4 3 0>,
				<DCC_READ 0x0BA600F4 3 0>,
				<DCC_READ 0x0BA70000 2 0>,
				<DCC_READ 0x0BA70018 1 0>,
				<DCC_READ 0x0BA70024 1 0>,
				<DCC_READ 0x0BA70030 5 0>,
				<DCC_READ 0x0BA7004C 4 0>,
				<DCC_READ 0x0BA70064 7 0>,
				<DCC_READ 0x0BA70088 1 0>,
				<DCC_READ 0x0BA70094 1 0>,
				<DCC_READ 0x0BA700A0 3 0>,
				<DCC_READ 0x0BA700B4 11 0>,
				<DCC_READ 0x0BA700E4 3 0>,
				<DCC_READ 0x0BA700F4 3 0>,
				<DCC_READ 0x0BA80000 3 0>,
				<DCC_READ 0x0BA80010 3 0>,
				<DCC_READ 0x0BA80024 1 0>,
				<DCC_READ 0x0BA8004C 4 0>,
				<DCC_READ 0x0BA80064 4 0>,
				<DCC_READ 0x0BA8007C 1 0>,
				<DCC_READ 0x0BA80088 1 0>,
				<DCC_READ 0x0BA80094 1 0>,
				<DCC_READ 0x0BA800A0 3 0>,
				<DCC_READ 0x0BA800B4 11 0>,
				<DCC_READ 0x0BA800E4 3 0>,
				<DCC_READ 0x0BA800F4 3 0>,
				<DCC_READ 0x0BA90000 3 0>,
				<DCC_READ 0x0BA90010 2 0>,
				<DCC_READ 0x0BA90058 2 0>,
				<DCC_READ 0x0BA900B4 11 0>,
				<DCC_READ 0x0BA900E4 3 0>,
				<DCC_READ 0x0BA900F4 3 0>,
				<DCC_READ 0x0BAA0000 3 0>,
				<DCC_READ 0x0BAA0010 2 0>,
				<DCC_READ 0x0BAA0050 2 0>,
				<DCC_READ 0x0BAA00B4 11 0>,
				<DCC_READ 0x0BAA00E4 3 0>,
				<DCC_READ 0x0BAA00F4 3 0>,
				<DCC_READ 0x0BAB0000 3 0>,
				<DCC_READ 0x0BAB0010 2 0>,
				<DCC_READ 0x0BAB0050 2 0>,
				<DCC_READ 0x0BAB00B4 11 0>,
				<DCC_READ 0x0BAB00E4 3 0>,
				<DCC_READ 0x0BAB00F4 3 0>,
				<DCC_READ 0x0BAC0000 3 0>,
				<DCC_READ 0x0BAC0010 2 0>,
				<DCC_READ 0x0BAC0024 1 0>,
				<DCC_READ 0x0BAC0030 2 0>,
				<DCC_READ 0x0BAC0040 1 0>,
				<DCC_READ 0x0BAC004C 1 0>,
				<DCC_READ 0x0BAC0058 4 0>,
				<DCC_READ 0x0BAC0070 6 0>,
				<DCC_READ 0x0BAC00A0 16 0>,
				<DCC_READ 0x0BAC00E4 3 0>,
				<DCC_READ 0x0BAC00F4 3 0>,
				<DCC_READ 0x0BAD0000 3 0>,
				<DCC_READ 0x0BAD0010 6 0>,
				<DCC_READ 0x0BAD0030 5 0>,
				<DCC_READ 0x0BAD004C 1 0>,
				<DCC_READ 0x0BAD0058 9 0>,
				<DCC_READ 0x0BAD0088 8 0>,
				<DCC_READ 0x0BAD00B4 11 0>,
				<DCC_READ 0x0BAD00E4 3 0>,
				<DCC_READ 0x0BAD00F4 3 0>,
				<DCC_READ 0x0BAE0000 3 0>,
				<DCC_READ 0x0BAE0010 3 0>,
				<DCC_READ 0x0BAE0024 1 0>,
				<DCC_READ 0x0BAE0030 5 0>,
				<DCC_READ 0x0BAE004C 13 0>,
				<DCC_READ 0x0BAE0088 1 0>,
				<DCC_READ 0x0BAE0094 1 0>,
				<DCC_READ 0x0BAE00A0 3 0>,
				<DCC_READ 0x0BAE00B4 11 0>,
				<DCC_READ 0x0BAE00E4 3 0>,
				<DCC_READ 0x0BAE00F4 3 0>,
				<DCC_READ 0x0BAF0000 3 0>,
				<DCC_READ 0x0BAF0010 2 0>,
				<DCC_READ 0x0BAF0024 1 0>,
				<DCC_READ 0x0BAF0030 2 0>,
				<DCC_READ 0x0BAF0040 1 0>,
				<DCC_READ 0x0BAF004C 1 0>,
				<DCC_READ 0x0BAF0058 4 0>,
				<DCC_READ 0x0BAF0070 6 0>,
				<DCC_READ 0x0BAF00A0 16 0>,
				<DCC_READ 0x0BAF00E4 3 0>,
				<DCC_READ 0x0BAF00F4 3 0>,
				<DCC_READ 0x0BBF0004 16 0>,
				<DCC_READ 0x0BBF0800 16 0>,
				<DCC_READ 0x0BBF0880 16 0>,
				<DCC_READ 0x0BBF1704 1 0>,
				<DCC_READ 0x0B201020 2 0>,
				<DCC_READ 0x0B201300 2 0>,
				<DCC_READ 0x0B20130C 1 0>,
				<DCC_READ 0x0B201314 1 0>,
				<DCC_READ 0x0B20131C 1 0>,
				<DCC_READ 0x0B2013C8 2 0>,
				<DCC_READ 0x0B2013D4 1 0>,
				<DCC_READ 0x0B2013DC 1 0>,
				<DCC_READ 0x0B2013E4 1 0>,
				<DCC_READ 0x0B201490 2 0>,
				<DCC_READ 0x0B20149C 1 0>,
				<DCC_READ 0x0B2014A4 1 0>,
				<DCC_READ 0x0B2014AC 1 0>,
				<DCC_READ 0x0B201558 2 0>,
				<DCC_READ 0x0B201564 1 0>,
				<DCC_READ 0x0B20156C 1 0>,
				<DCC_READ 0x0B201574 1 0>,
				<DCC_READ 0x0B204500 1 0>,
				<DCC_READ 0x0B211020 2 0>,
				<DCC_READ 0x0B211300 2 0>,
				<DCC_READ 0x0B21130C 1 0>,
				<DCC_READ 0x0B211314 1 0>,
				<DCC_READ 0x0B21131C 1 0>,
				<DCC_READ 0x0B2113C8 2 0>,
				<DCC_READ 0x0B2113D4 1 0>,
				<DCC_READ 0x0B2113DC 1 0>,
				<DCC_READ 0x0B2113E4 1 0>,
				<DCC_READ 0x0B211490 2 0>,
				<DCC_READ 0x0B21149C 1 0>,
				<DCC_READ 0x0B2114A4 1 0>,
				<DCC_READ 0x0B2114AC 1 0>,
				<DCC_READ 0x0B211558 2 0>,
				<DCC_READ 0x0B211564 1 0>,
				<DCC_READ 0x0B21156C 1 0>,
				<DCC_READ 0x0B211574 1 0>,
				<DCC_READ 0x0B221020 2 0>,
				<DCC_READ 0x0B221300 2 0>,
				<DCC_READ 0x0B22130C 1 0>,
				<DCC_READ 0x0B221314 1 0>,
				<DCC_READ 0x0B22131C 1 0>,
				<DCC_READ 0x0B2213C8 2 0>,
				<DCC_READ 0x0B2213D4 1 0>,
				<DCC_READ 0x0B2213DC 1 0>,
				<DCC_READ 0x0B2213E4 1 0>,
				<DCC_READ 0x0B221490 2 0>,
				<DCC_READ 0x0B22149C 1 0>,
				<DCC_READ 0x0B2214A4 1 0>,
				<DCC_READ 0x0B2214AC 1 0>,
				<DCC_READ 0x0B221558 2 0>,
				<DCC_READ 0x0B221564 1 0>,
				<DCC_READ 0x0B22156C 1 0>,
				<DCC_READ 0x0B221574 1 0>,
				<DCC_READ 0x0B231020 2 0>,
				<DCC_READ 0x0B231300 2 0>,
				<DCC_READ 0x0B23130C 1 0>,
				<DCC_READ 0x0B231314 1 0>,
				<DCC_READ 0x0B23131C 1 0>,
				<DCC_READ 0x0B2313C8 2 0>,
				<DCC_READ 0x0B2313D4 1 0>,
				<DCC_READ 0x0B2313DC 1 0>,
				<DCC_READ 0x0B2313E4 1 0>,
				<DCC_READ 0x0B231490 2 0>,
				<DCC_READ 0x0B23149C 1 0>,
				<DCC_READ 0x0B2314A4 1 0>,
				<DCC_READ 0x0B2314AC 1 0>,
				<DCC_READ 0x0B231558 2 0>,
				<DCC_READ 0x0B231564 1 0>,
				<DCC_READ 0x0B23156C 1 0>,
				<DCC_READ 0x0B231574 1 0>,
				<DCC_READ 0x0B241020 2 0>,
				<DCC_READ 0x0B241300 2 0>,
				<DCC_READ 0x0B24130C 1 0>,
				<DCC_READ 0x0B241314 1 0>,
				<DCC_READ 0x0B24131C 1 0>,
				<DCC_READ 0x0B2413C8 2 0>,
				<DCC_READ 0x0B2413D4 1 0>,
				<DCC_READ 0x0B2413DC 1 0>,
				<DCC_READ 0x0B2413E4 1 0>,
				<DCC_READ 0x0B241490 2 0>,
				<DCC_READ 0x0B24149C 1 0>,
				<DCC_READ 0x0B2414A4 1 0>,
				<DCC_READ 0x0B2414AC 1 0>,
				<DCC_READ 0x0B244500 1 0>,
				<DCC_READ 0x0B251020 2 0>,
				<DCC_READ 0x0B251300 2 0>,
				<DCC_READ 0x0B25130C 1 0>,
				<DCC_READ 0x0B251314 1 0>,
				<DCC_READ 0x0B25131C 1 0>,
				<DCC_READ 0x0B2513C8 2 0>,
				<DCC_READ 0x0B2513D4 1 0>,
				<DCC_READ 0x0B2513DC 1 0>,
				<DCC_READ 0x0B2513E4 1 0>,
				<DCC_READ 0x0B251490 2 0>,
				<DCC_READ 0x0B25149C 1 0>,
				<DCC_READ 0x0B2514A4 1 0>,
				<DCC_READ 0x0B2514AC 1 0>,
				<DCC_READ 0x0B254500 1 0>,
				<DCC_READ 0x0B2C1020 2 0>,
				<DCC_READ 0x0B2C1300 2 0>,
				<DCC_READ 0x0B2C130C 1 0>,
				<DCC_READ 0x0B2C1314 1 0>,
				<DCC_READ 0x0B2C131C 1 0>,
				<DCC_READ 0x0B2C13C8 2 0>,
				<DCC_READ 0x0B2C13D4 1 0>,
				<DCC_READ 0x0B2C13DC 1 0>,
				<DCC_READ 0x0B2C13E4 1 0>,
				<DCC_READ 0x0B2C1490 2 0>,
				<DCC_READ 0x0B2C149C 1 0>,
				<DCC_READ 0x0B2C14A4 1 0>,
				<DCC_READ 0x0B2C14AC 1 0>,
				<DCC_READ 0x0B2C4500 1 0>,
				<DCC_READ 0x0B2D1020 2 0>,
				<DCC_READ 0x0B2D1300 2 0>,
				<DCC_READ 0x0B2D130C 1 0>,
				<DCC_READ 0x0B2D1314 1 0>,
				<DCC_READ 0x0B2D131C 1 0>,
				<DCC_READ 0x0B2D13C8 2 0>,
				<DCC_READ 0x0B2D13D4 1 0>,
				<DCC_READ 0x0B2D13DC 1 0>,
				<DCC_READ 0x0B2D13E4 1 0>,
				<DCC_READ 0x0B2D1490 2 0>,
				<DCC_READ 0x0B2D149C 1 0>,
				<DCC_READ 0x0B2D14A4 1 0>,
				<DCC_READ 0x0B2D14AC 1 0>,
				<DCC_READ 0x0B2D4500 1 0>,
				<DCC_READ 0x0B5E2300 1 0>,
				<DCC_READ 0x0B5E2310 1 0>,
				<DCC_READ 0x0B5E2320 1 0>,
				<DCC_READ 0x0B5E2330 1 0>;
		};

		link_list_2 {
			qcom,curr-link-list = <6>;
			qcom,data-sink = "sram";
			qcom,link-list = <DCC_READ 0x18221270 1 0>,
				<DCC_READ 0x18221284 1 0>,
				<DCC_READ 0x18221298 1 0>,
				<DCC_READ 0x182212ac 1 0>,
				<DCC_READ 0x182212c0 1 0>,
				<DCC_READ 0x182212d4 1 0>,
				<DCC_READ 0x182212e8 1 0>,
				<DCC_READ 0x182212fc 1 0>,
				<DCC_READ 0x18221310 1 0>,
				<DCC_READ 0x18221324 1 0>,
				<DCC_READ 0x18221338 1 0>,
				<DCC_READ 0x1822134c 1 0>,
				<DCC_READ 0x18221360 1 0>,
				<DCC_READ 0x18221374 1 0>,
				<DCC_READ 0x18221388 1 0>,
				<DCC_READ 0x1822139c 1 0>,
				<DCC_READ 0x18221510 1 0>,
				<DCC_READ 0x18221524 1 0>,
				<DCC_READ 0x18221538 1 0>,
				<DCC_READ 0x1822154c 1 0>,
				<DCC_READ 0x18221560 1 0>,
				<DCC_READ 0x18221574 1 0>,
				<DCC_READ 0x18221588 1 0>,
				<DCC_READ 0x1822159c 1 0>,
				<DCC_READ 0x182215b0 1 0>,
				<DCC_READ 0x182215c4 1 0>,
				<DCC_READ 0x182215d8 1 0>,
				<DCC_READ 0x182215ec 1 0>,
				<DCC_READ 0x18221600 1 0>,
				<DCC_READ 0x18221614 1 0>,
				<DCC_READ 0x18221628 1 0>,
				<DCC_READ 0x1822163c 1 0>,
				<DCC_READ 0x18221a50 1 0>,
				<DCC_READ 0x18221a64 1 0>,
				<DCC_READ 0x18221a78 1 0>,
				<DCC_READ 0x18221a8c 1 0>,
				<DCC_READ 0x18221aa0 1 0>,
				<DCC_READ 0x18221ab4 1 0>,
				<DCC_READ 0x18221ac8 1 0>,
				<DCC_READ 0x18221adc 1 0>,
				<DCC_READ 0x18221af0 1 0>,
				<DCC_READ 0x18221b04 1 0>,
				<DCC_READ 0x18221b18 1 0>,
				<DCC_READ 0x18221b2c 1 0>,
				<DCC_READ 0x18221b40 1 0>,
				<DCC_READ 0x18221b54 1 0>,
				<DCC_READ 0x18221b68 1 0>,
				<DCC_READ 0x18221b7c 1 0>,
				<DCC_READ 0x18221cf0 1 0>,
				<DCC_READ 0x18221d04 1 0>,
				<DCC_READ 0x18221d18 1 0>,
				<DCC_READ 0x18221d2c 1 0>,
				<DCC_READ 0x18221d40 1 0>,
				<DCC_READ 0x18221d54 1 0>,
				<DCC_READ 0x18221d68 1 0>,
				<DCC_READ 0x18221d7c 1 0>,
				<DCC_READ 0x18221d90 1 0>,
				<DCC_READ 0x18221da4 1 0>,
				<DCC_READ 0x18221db8 1 0>,
				<DCC_READ 0x18221dcc 1 0>,
				<DCC_READ 0x18221de0 1 0>,
				<DCC_READ 0x18221df4 1 0>,
				<DCC_READ 0x18221e08 1 0>,
				<DCC_READ 0x18221e1c 1 0>,
				<DCC_READ 0x18221274 1 0>,
				<DCC_READ 0x18221288 1 0>,
				<DCC_READ 0x1822129c 1 0>,
				<DCC_READ 0x182212b0 1 0>,
				<DCC_READ 0x182212c4 1 0>,
				<DCC_READ 0x182212d8 1 0>,
				<DCC_READ 0x182212ec 1 0>,
				<DCC_READ 0x18221300 1 0>,
				<DCC_READ 0x18221314 1 0>,
				<DCC_READ 0x18221328 1 0>,
				<DCC_READ 0x1822133c 1 0>,
				<DCC_READ 0x18221350 1 0>,
				<DCC_READ 0x18221364 1 0>,
				<DCC_READ 0x18221378 1 0>,
				<DCC_READ 0x1822138c 1 0>,
				<DCC_READ 0x182213a0 1 0>,
				<DCC_READ 0x18221514 1 0>,
				<DCC_READ 0x18221528 1 0>,
				<DCC_READ 0x1822153c 1 0>,
				<DCC_READ 0x18221550 1 0>,
				<DCC_READ 0x18221564 1 0>,
				<DCC_READ 0x18221578 1 0>,
				<DCC_READ 0x1822158c 1 0>,
				<DCC_READ 0x182215a0 1 0>,
				<DCC_READ 0x182215b4 1 0>,
				<DCC_READ 0x182215c8 1 0>,
				<DCC_READ 0x182215dc 1 0>,
				<DCC_READ 0x182215f0 1 0>,
				<DCC_READ 0x18221604 1 0>,
				<DCC_READ 0x18221618 1 0>,
				<DCC_READ 0x1822162c 1 0>,
				<DCC_READ 0x18221640 1 0>,
				<DCC_READ 0x18221a54 1 0>,
				<DCC_READ 0x18221a68 1 0>,
				<DCC_READ 0x18221a7c 1 0>,
				<DCC_READ 0x18221a90 1 0>,
				<DCC_READ 0x18221aa4 1 0>,
				<DCC_READ 0x18221ab8 1 0>,
				<DCC_READ 0x18221acc 1 0>,
				<DCC_READ 0x18221ae0 1 0>,
				<DCC_READ 0x18221af4 1 0>,
				<DCC_READ 0x18221b08 1 0>,
				<DCC_READ 0x18221b1c 1 0>,
				<DCC_READ 0x18221b30 1 0>,
				<DCC_READ 0x18221b44 1 0>,
				<DCC_READ 0x18221b58 1 0>,
				<DCC_READ 0x18221b6c 1 0>,
				<DCC_READ 0x18221b80 1 0>,
				<DCC_READ 0x18221cf4 1 0>,
				<DCC_READ 0x18221d08 1 0>,
				<DCC_READ 0x18221d1c 1 0>,
				<DCC_READ 0x18221d30 1 0>,
				<DCC_READ 0x18221d44 1 0>,
				<DCC_READ 0x18221d58 1 0>,
				<DCC_READ 0x18221d6c 1 0>,
				<DCC_READ 0x18221d80 1 0>,
				<DCC_READ 0x18221d94 1 0>,
				<DCC_READ 0x18221da8 1 0>,
				<DCC_READ 0x18221dbc 1 0>,
				<DCC_READ 0x18221dd0 1 0>,
				<DCC_READ 0x18221de4 1 0>,
				<DCC_READ 0x18221df8 1 0>,
				<DCC_READ 0x18221e0c 1 0>,
				<DCC_READ 0x18221e20 1 0>,
				<DCC_READ 0x18221278 1 0>,
				<DCC_READ 0x1822128c 1 0>,
				<DCC_READ 0x182212a0 1 0>,
				<DCC_READ 0x182212b4 1 0>,
				<DCC_READ 0x182212c8 1 0>,
				<DCC_READ 0x182212dc 1 0>,
				<DCC_READ 0x182212f0 1 0>,
				<DCC_READ 0x18221304 1 0>,
				<DCC_READ 0x18221318 1 0>,
				<DCC_READ 0x1822132c 1 0>,
				<DCC_READ 0x18221340 1 0>,
				<DCC_READ 0x18221354 1 0>,
				<DCC_READ 0x18221368 1 0>,
				<DCC_READ 0x1822137c 1 0>,
				<DCC_READ 0x18221390 1 0>,
				<DCC_READ 0x182213a4 1 0>,
				<DCC_READ 0x18221518 1 0>,
				<DCC_READ 0x1822152c 1 0>,
				<DCC_READ 0x18221540 1 0>,
				<DCC_READ 0x18221554 1 0>,
				<DCC_READ 0x18221568 1 0>,
				<DCC_READ 0x1822157c 1 0>,
				<DCC_READ 0x18221590 1 0>,
				<DCC_READ 0x182215a4 1 0>,
				<DCC_READ 0x182215b8 1 0>,
				<DCC_READ 0x182215cc 1 0>,
				<DCC_READ 0x182215e0 1 0>,
				<DCC_READ 0x182215f4 1 0>,
				<DCC_READ 0x18221608 1 0>,
				<DCC_READ 0x1822161c 1 0>,
				<DCC_READ 0x18221630 1 0>,
				<DCC_READ 0x18221644 1 0>,
				<DCC_READ 0x18221a58 1 0>,
				<DCC_READ 0x18221a6c 1 0>,
				<DCC_READ 0x18221a80 1 0>,
				<DCC_READ 0x18221a94 1 0>,
				<DCC_READ 0x18221aa8 1 0>,
				<DCC_READ 0x18221abc 1 0>,
				<DCC_READ 0x18221ad0 1 0>,
				<DCC_READ 0x18221ae4 1 0>,
				<DCC_READ 0x18221af8 1 0>,
				<DCC_READ 0x18221b0c 1 0>,
				<DCC_READ 0x18221b20 1 0>,
				<DCC_READ 0x18221b34 1 0>,
				<DCC_READ 0x18221b48 1 0>,
				<DCC_READ 0x18221b5c 1 0>,
				<DCC_READ 0x18221b70 1 0>,
				<DCC_READ 0x18221b84 1 0>,
				<DCC_READ 0x18221cf8 1 0>,
				<DCC_READ 0x18221d0c 1 0>,
				<DCC_READ 0x18221d20 1 0>,
				<DCC_READ 0x18221d34 1 0>,
				<DCC_READ 0x18221d48 1 0>,
				<DCC_READ 0x18221d5c 1 0>,
				<DCC_READ 0x18221d70 1 0>,
				<DCC_READ 0x18221d84 1 0>,
				<DCC_READ 0x18221d98 1 0>,
				<DCC_READ 0x18221dac 1 0>,
				<DCC_READ 0x18221dc0 1 0>,
				<DCC_READ 0x18221dd4 1 0>,
				<DCC_READ 0x18221de8 1 0>,
				<DCC_READ 0x18221dfc 1 0>,
				<DCC_READ 0x18221e10 1 0>,
				<DCC_READ 0x18221e24 1 0>,
				<DCC_READ 0x18210408 1 0>,
				<DCC_READ 0x18220408 1 0>,
				<DCC_READ 0x18230408 1 0>,
				<DCC_READ 0x18440008 14 0>,
				<DCC_READ 0x18441000 7 0>,
				<DCC_READ 0x1FFD008 8 0>;
		};
	};

	mem_dump {
		compatible = "qcom,mem-dump";
		memory-region = <&dump_mem>;

		c0_context {
			qcom,dump-size = <0x800>;
			qcom,dump-id = <0x0>;
		};

		c100_context {
			qcom,dump-size = <0x800>;
			qcom,dump-id = <0x1>;
		};

		c200_context {
			qcom,dump-size = <0x800>;
			qcom,dump-id = <0x2>;
		};

		c300_context {
			qcom,dump-size = <0x800>;
			qcom,dump-id = <0x3>;
		};

		c400_context {
			qcom,dump-size = <0x800>;
			qcom,dump-id = <0x4>;
		};

		c500_context {
			qcom,dump-size = <0x800>;
			qcom,dump-id = <0x5>;
		};

		c600_context {
			qcom,dump-size = <0x800>;
			qcom,dump-id = <0x6>;
		};

		c700_context {
			qcom,dump-size = <0x800>;
			qcom,dump-id = <0x7>;
		};

		rpmh {
			qcom,dump-size = <0x2000000>;
			qcom,dump-id = <0xec>;
		};

		rpm_sw {
			qcom,dump-size = <0x28000>;
			qcom,dump-id = <0xea>;
		};

		pmic {
			qcom,dump-size = <0x80000>;
			qcom,dump-id = <0xe4>;
		};

		fcm {
			qcom,dump-size = <0x8400>;
			qcom,dump-id = <0xee>;
		};

		tmc_etf {
			qcom,dump-size = <0x10000>;
			qcom,dump-id = <0xf0>;
		};

		etf_swao {
			qcom,dump-size = <0x8400>;
			qcom,dump-id = <0xf1>;
		};

		etr_reg {
			qcom,dump-size = <0x1000>;
			qcom,dump-id = <0x100>;
		};

		etf_reg {
			qcom,dump-size = <0x1000>;
			qcom,dump-id = <0x101>;
		};

		etfswao_reg {
			qcom,dump-size = <0x1000>;
			qcom,dump-id = <0x102>;
		};

		misc_data {
			qcom,dump-size = <0x1000>;
			qcom,dump-id = <0xe8>;
		};

		l1_icache0 {
			qcom,dump-size = <0x26100>;
			qcom,dump-id = <0x60>;
		};

		l1_icache100 {
			qcom,dump-size = <0x26100>;
			qcom,dump-id = <0x61>;
		};

		l1_icache200 {
			qcom,dump-size = <0x26100>;
			qcom,dump-id = <0x62>;
		};

		l1_icache300 {
			qcom,dump-size = <0x26100>;
			qcom,dump-id = <0x63>;
		};

		l1_icache10000 {
			qcom,dump-size = <0x26100>;
			qcom,dump-id = <0x64>;
		};

		l1_icache10100 {
			qcom,dump-size = <0x26100>;
			qcom,dump-id = <0x65>;
		};

		l1_icache10200 {
			qcom,dump-size = <0x26100>;
			qcom,dump-id = <0x66>;
		};

		l1_icache10300 {
			qcom,dump-size = <0x26100>;
			qcom,dump-id = <0x67>;
		};

		l1_dcache0 {
			qcom,dump-size = <0x12100>;
			qcom,dump-id = <0x80>;
		};

		l1_dcache100 {
			qcom,dump-size = <0x12100>;
			qcom,dump-id = <0x81>;
		};

		l1_dcache200 {
			qcom,dump-size = <0x12100>;
			qcom,dump-id = <0x82>;
		};

		l1_dcache300 {
			qcom,dump-size = <0x12100>;
			qcom,dump-id = <0x83>;
		};

		l1_dcache10000 {
			qcom,dump-size = <0x12100>;
			qcom,dump-id = <0x84>;
		};

		l1_dcache10100 {
			qcom,dump-size = <0x12100>;
			qcom,dump-id = <0x85>;
		};

		l1_dcache10200 {
			qcom,dump-size = <0x12100>;
			qcom,dump-id = <0x86>;
		};

		l1_dcache10300 {
			qcom,dump-size = <0x12100>;
			qcom,dump-id = <0x87>;
		};

		l1_itlb10000 {
			qcom,dump-size = <0x300>;
			qcom,dump-id = <0x24>;
		};

		l1_itlb10100 {
			qcom,dump-size = <0x300>;
			qcom,dump-id = <0x25>;
		};

		l1_itlb10200 {
			qcom,dump-size = <0x300>;
			qcom,dump-id = <0x26>;
		};

		l1_itlb10300 {
			qcom,dump-size = <0x300>;
			qcom,dump-id = <0x27>;
		};

		l1_dtlb10000 {
			qcom,dump-size = <0x300>;
			qcom,dump-id = <0x44>;
		};

		l1_dtlb10100 {
			qcom,dump-size = <0x300>;
			qcom,dump-id = <0x45>;
		};

		l1_dtlb10200 {
			qcom,dump-size = <0x300>;
			qcom,dump-id = <0x46>;
		};

		l1_dtlb10300 {
			qcom,dump-size = <0x300>;
			qcom,dump-id = <0x47>;
		};

		l2_cache10000 {
			qcom,dump-size = <0x90100>;
			qcom,dump-id = <0xc4>;
		};

		l2_cache10100 {
			qcom,dump-size = <0x90100>;
			qcom,dump-id = <0xc5>;
		};

		l2_cache10200 {
			qcom,dump-size = <0x90100>;
			qcom,dump-id = <0xc6>;
		};

		l2_cache10300 {
			qcom,dump-size = <0x90100>;
			qcom,dump-id = <0xc7>;
		};

		l2_tlb0 {
			qcom,dump-size = <0x6100>;
			qcom,dump-id = <0x120>;
		};

		l2_tlb100 {
			qcom,dump-size = <0x6100>;
			qcom,dump-id = <0x121>;
		};

		l2_tlb200 {
			qcom,dump-size = <0x6100>;
			qcom,dump-id = <0x122>;
		};

		l2_tlb300 {
			qcom,dump-size = <0x6100>;
			qcom,dump-id = <0x123>;
		};

		l2_tlb10000 {
			qcom,dump-size = <0x6100>;
			qcom,dump-id = <0x124>;
		};

		l2_tlb10100 {
			qcom,dump-size = <0x6100>;
			qcom,dump-id = <0x125>;
		};

		l2_tlb10200 {
			qcom,dump-size = <0x6100>;
			qcom,dump-id = <0x126>;
		};

		l2_tlb10300 {
			qcom,dump-size = <0x6100>;
			qcom,dump-id = <0x127>;
		};

		c0_scandump: c0_scandump {
			qcom,dump-size = <0x40000>;
			qcom,dump-id = <0x130>;
		};

		c100_scandump: c100_scandump {
			qcom,dump-size = <0x40000>;
			qcom,dump-id = <0x131>;
		};

		c200_scandump: c200_scandump {
			qcom,dump-size = <0x40000>;
			qcom,dump-id = <0x132>;
		};

		c300_scandump: c300_scandump {
			qcom,dump-size = <0x40000>;
			qcom,dump-id = <0x133>;
		};

		c10000_scandump: c10000_scandump {
			qcom,dump-size = <0x40000>;
			qcom,dump-id = <0x134>;
		};

		c10100_scandump: c10100_scandump {
			qcom,dump-size = <0x40000>;
			qcom,dump-id = <0x135>;
		};

		c10200_scandump: c10200_scandump {
			qcom,dump-size = <0x40000>;
			qcom,dump-id = <0x136>;
		};

		c10300_scandump: c10300_scandump {
			qcom,dump-size = <0x40000>;
			qcom,dump-id = <0x137>;
		};

		cpuss_reg: cpuss_reg {
			qcom,dump-size = <0x20000>;
			qcom,dump-id = <0xef>;
		};
	};
};
